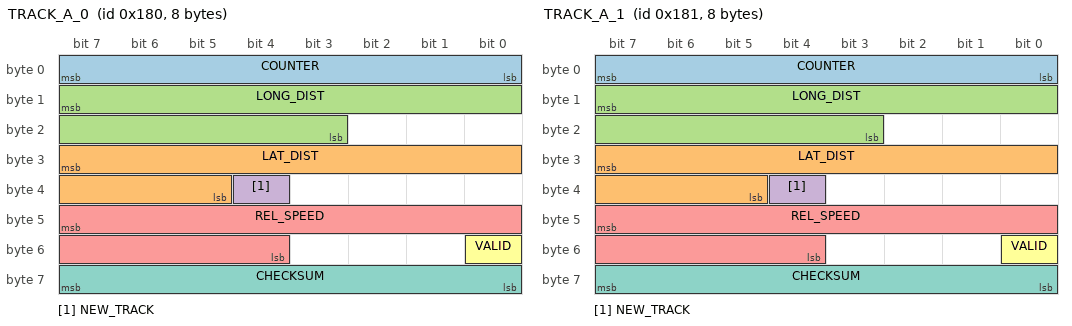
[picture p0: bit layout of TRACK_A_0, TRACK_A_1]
BO_ 384 TRACK_A_0: 8 XXX
 SG_ COUNTER : 7|8@0+ (1,0) [0|255] "" XXX
 SG_ LAT_DIST : 31|11@0- (0.04,0) [-50|50] "m" XXX
 SG_ LONG_DIST : 15|13@0+ (0.04,0) [0|300] "m" XXX
 SG_ NEW_TRACK : 36|1@0+ (1,0) [0|1] "" XXX
 SG_ REL_SPEED : 47|12@0- (0.025,0) [-100|100] "m/s" XXX
 SG_ VALID : 48|1@0+ (1,0) [0|1] "" XXX
 SG_ CHECKSUM : 63|8@0+ (1,0) [0|255] "" XXX

BO_ 385 TRACK_A_1: 8 XXX
 SG_ COUNTER : 7|8@0+ (1,0) [0|255] "" XXX
 SG_ LAT_DIST : 31|11@0- (0.04,0) [-50|50] "m" XXX
 SG_ LONG_DIST : 15|13@0+ (0.04,0) [0|300] "m" XXX
 SG_ NEW_TRACK : 36|1@0+ (1,0) [0|1] "" XXX
 SG_ REL_SPEED : 47|12@0- (0.025,0) [-100|100] "m/s" XXX
 SG_ VALID : 48|1@0+ (1,0) [0|1] "" XXX
 SG_ CHECKSUM : 63|8@0+ (1,0) [0|255] "" XXX

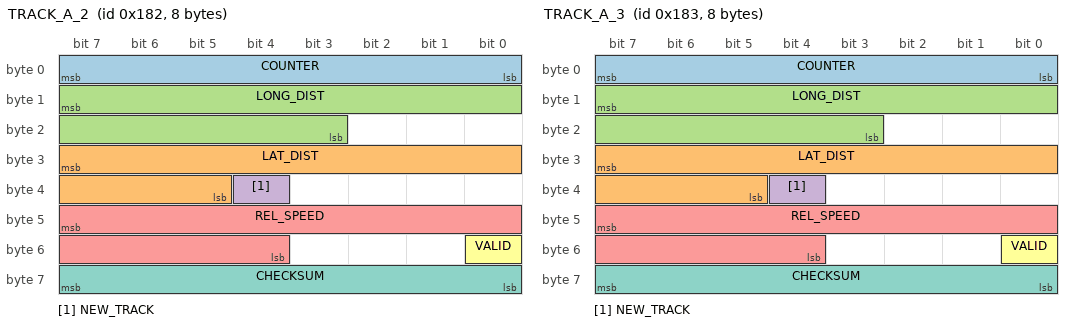
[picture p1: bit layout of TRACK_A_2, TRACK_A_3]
BO_ 386 TRACK_A_2: 8 XXX
 SG_ COUNTER : 7|8@0+ (1,0) [0|255] "" XXX
 SG_ LAT_DIST : 31|11@0- (0.04,0) [-50|50] "m" XXX
 SG_ LONG_DIST : 15|13@0+ (0.04,0) [0|300] "m" XXX
 SG_ NEW_TRACK : 36|1@0+ (1,0) [0|1] "" XXX
 SG_ REL_SPEED : 47|12@0- (0.025,0) [-100|100] "m/s" XXX
 SG_ VALID : 48|1@0+ (1,0) [0|1] "" XXX
 SG_ CHECKSUM : 63|8@0+ (1,0) [0|255] "" XXX

BO_ 387 TRACK_A_3: 8 XXX
 SG_ COUNTER : 7|8@0+ (1,0) [0|255] "" XXX
 SG_ LAT_DIST : 31|11@0- (0.04,0) [-50|50] "m" XXX
 SG_ LONG_DIST : 15|13@0+ (0.04,0) [0|300] "m" XXX
 SG_ NEW_TRACK : 36|1@0+ (1,0) [0|1] "" XXX
 SG_ REL_SPEED : 47|12@0- (0.025,0) [-100|100] "m/s" XXX
 SG_ VALID : 48|1@0+ (1,0) [0|1] "" XXX
 SG_ CHECKSUM : 63|8@0+ (1,0) [0|255] "" XXX

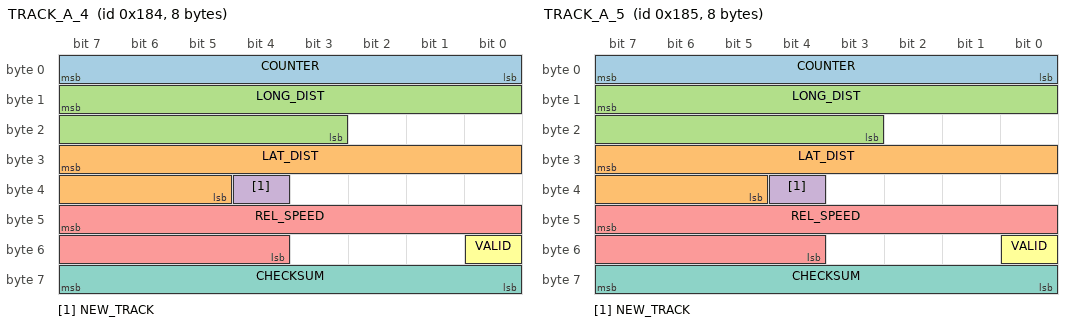
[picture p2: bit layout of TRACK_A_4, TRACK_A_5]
BO_ 388 TRACK_A_4: 8 XXX
 SG_ COUNTER : 7|8@0+ (1,0) [0|255] "" XXX
 SG_ LAT_DIST : 31|11@0- (0.04,0) [-50|50] "m" XXX
 SG_ LONG_DIST : 15|13@0+ (0.04,0) [0|300] "m" XXX
 SG_ NEW_TRACK : 36|1@0+ (1,0) [0|1] "" XXX
 SG_ REL_SPEED : 47|12@0- (0.025,0) [-100|100] "m/s" XXX
 SG_ VALID : 48|1@0+ (1,0) [0|1] "" XXX
 SG_ CHECKSUM : 63|8@0+ (1,0) [0|255] "" XXX

BO_ 389 TRACK_A_5: 8 XXX
 SG_ COUNTER : 7|8@0+ (1,0) [0|255] "" XXX
 SG_ LAT_DIST : 31|11@0- (0.04,0) [-50|50] "m" XXX
 SG_ LONG_DIST : 15|13@0+ (0.04,0) [0|300] "m" XXX
 SG_ NEW_TRACK : 36|1@0+ (1,0) [0|1] "" XXX
 SG_ REL_SPEED : 47|12@0- (0.025,0) [-100|100] "m/s" XXX
 SG_ VALID : 48|1@0+ (1,0) [0|1] "" XXX
 SG_ CHECKSUM : 63|8@0+ (1,0) [0|255] "" XXX

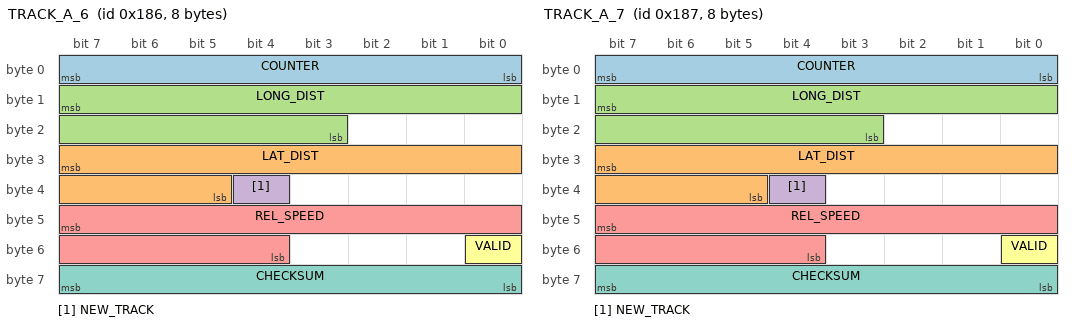
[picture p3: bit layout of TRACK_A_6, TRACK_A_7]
BO_ 390 TRACK_A_6: 8 XXX
 SG_ COUNTER : 7|8@0+ (1,0) [0|255] "" XXX
 SG_ LAT_DIST : 31|11@0- (0.04,0) [-50|50] "m" XXX
 SG_ LONG_DIST : 15|13@0+ (0.04,0) [0|300] "m" XXX
 SG_ NEW_TRACK : 36|1@0+ (1,0) [0|1] "" XXX
 SG_ REL_SPEED : 47|12@0- (0.025,0) [-100|100] "m/s" XXX
 SG_ VALID : 48|1@0+ (1,0) [0|1] "" XXX
 SG_ CHECKSUM : 63|8@0+ (1,0) [0|255] "" XXX

BO_ 391 TRACK_A_7: 8 XXX
 SG_ COUNTER : 7|8@0+ (1,0) [0|255] "" XXX
 SG_ LAT_DIST : 31|11@0- (0.04,0) [-50|50] "m" XXX
 SG_ LONG_DIST : 15|13@0+ (0.04,0) [0|300] "m" XXX
 SG_ NEW_TRACK : 36|1@0+ (1,0) [0|1] "" XXX
 SG_ REL_SPEED : 47|12@0- (0.025,0) [-100|100] "m/s" XXX
 SG_ VALID : 48|1@0+ (1,0) [0|1] "" XXX
 SG_ CHECKSUM : 63|8@0+ (1,0) [0|255] "" XXX

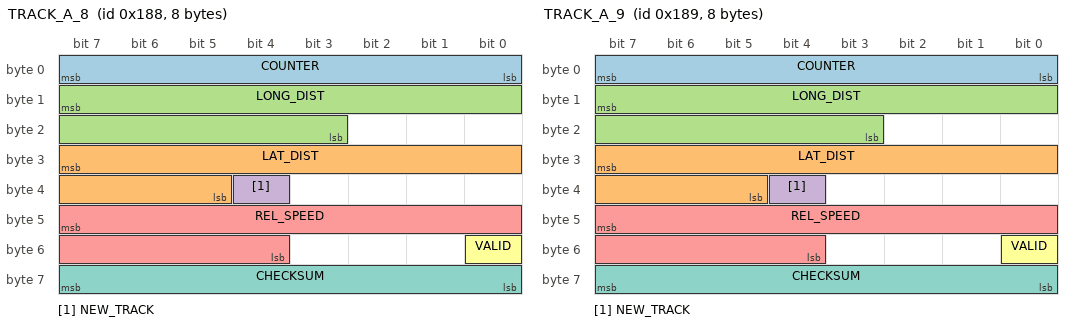
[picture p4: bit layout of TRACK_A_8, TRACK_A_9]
BO_ 392 TRACK_A_8: 8 XXX
 SG_ COUNTER : 7|8@0+ (1,0) [0|255] "" XXX
 SG_ LAT_DIST : 31|11@0- (0.04,0) [-50|50] "m" XXX
 SG_ LONG_DIST : 15|13@0+ (0.04,0) [0|300] "m" XXX
 SG_ NEW_TRACK : 36|1@0+ (1,0) [0|1] "" XXX
 SG_ REL_SPEED : 47|12@0- (0.025,0) [-100|100] "m/s" XXX
 SG_ VALID : 48|1@0+ (1,0) [0|1] "" XXX
 SG_ CHECKSUM : 63|8@0+ (1,0) [0|255] "" XXX

BO_ 393 TRACK_A_9: 8 XXX
 SG_ COUNTER : 7|8@0+ (1,0) [0|255] "" XXX
 SG_ LAT_DIST : 31|11@0- (0.04,0) [-50|50] "m" XXX
 SG_ LONG_DIST : 15|13@0+ (0.04,0) [0|300] "m" XXX
 SG_ NEW_TRACK : 36|1@0+ (1,0) [0|1] "" XXX
 SG_ REL_SPEED : 47|12@0- (0.025,0) [-100|100] "m/s" XXX
 SG_ VALID : 48|1@0+ (1,0) [0|1] "" XXX
 SG_ CHECKSUM : 63|8@0+ (1,0) [0|255] "" XXX

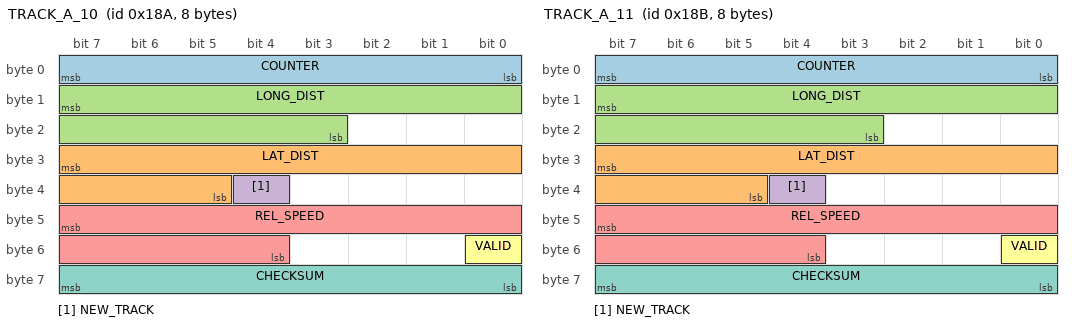
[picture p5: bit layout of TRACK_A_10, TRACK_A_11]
BO_ 394 TRACK_A_10: 8 XXX
 SG_ COUNTER : 7|8@0+ (1,0) [0|255] "" XXX
 SG_ LAT_DIST : 31|11@0- (0.04,0) [-50|50] "m" XXX
 SG_ LONG_DIST : 15|13@0+ (0.04,0) [0|300] "m" XXX
 SG_ NEW_TRACK : 36|1@0+ (1,0) [0|1] "" XXX
 SG_ REL_SPEED : 47|12@0- (0.025,0) [-100|100] "m/s" XXX
 SG_ VALID : 48|1@0+ (1,0) [0|1] "" XXX
 SG_ CHECKSUM : 63|8@0+ (1,0) [0|255] "" XXX

BO_ 395 TRACK_A_11: 8 XXX
 SG_ COUNTER : 7|8@0+ (1,0) [0|255] "" XXX
 SG_ LAT_DIST : 31|11@0- (0.04,0) [-50|50] "m" XXX
 SG_ LONG_DIST : 15|13@0+ (0.04,0) [0|300] "m" XXX
 SG_ NEW_TRACK : 36|1@0+ (1,0) [0|1] "" XXX
 SG_ REL_SPEED : 47|12@0- (0.025,0) [-100|100] "m/s" XXX
 SG_ VALID : 48|1@0+ (1,0) [0|1] "" XXX
 SG_ CHECKSUM : 63|8@0+ (1,0) [0|255] "" XXX

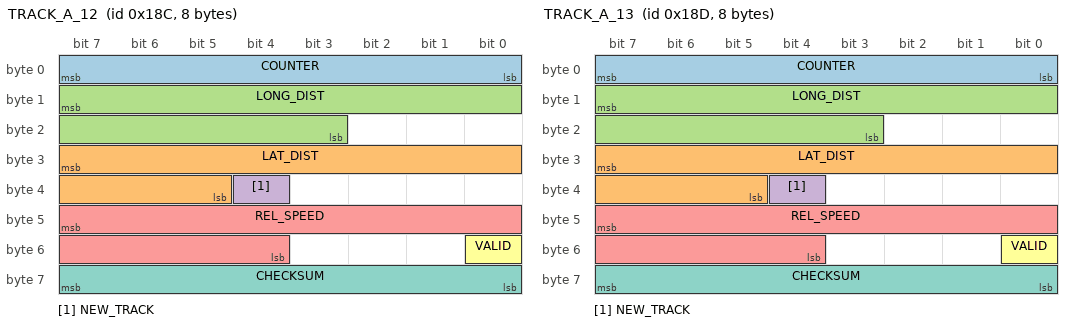
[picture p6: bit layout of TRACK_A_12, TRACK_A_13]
BO_ 396 TRACK_A_12: 8 XXX
 SG_ COUNTER : 7|8@0+ (1,0) [0|255] "" XXX
 SG_ LAT_DIST : 31|11@0- (0.04,0) [-50|50] "m" XXX
 SG_ LONG_DIST : 15|13@0+ (0.04,0) [0|300] "m" XXX
 SG_ NEW_TRACK : 36|1@0+ (1,0) [0|1] "" XXX
 SG_ REL_SPEED : 47|12@0- (0.025,0) [-100|100] "m/s" XXX
 SG_ VALID : 48|1@0+ (1,0) [0|1] "" XXX
 SG_ CHECKSUM : 63|8@0+ (1,0) [0|255] "" XXX

BO_ 397 TRACK_A_13: 8 XXX
 SG_ COUNTER : 7|8@0+ (1,0) [0|255] "" XXX
 SG_ LAT_DIST : 31|11@0- (0.04,0) [-50|50] "m" XXX
 SG_ LONG_DIST : 15|13@0+ (0.04,0) [0|300] "m" XXX
 SG_ NEW_TRACK : 36|1@0+ (1,0) [0|1] "" XXX
 SG_ REL_SPEED : 47|12@0- (0.025,0) [-100|100] "m/s" XXX
 SG_ VALID : 48|1@0+ (1,0) [0|1] "" XXX
 SG_ CHECKSUM : 63|8@0+ (1,0) [0|255] "" XXX

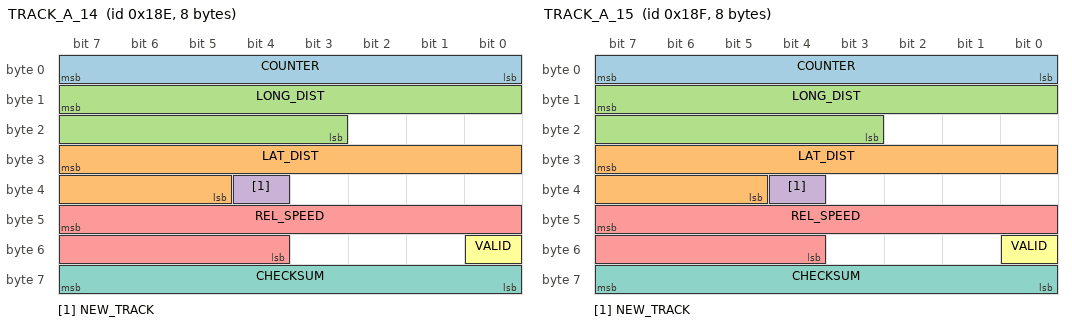
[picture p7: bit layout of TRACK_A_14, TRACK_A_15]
BO_ 398 TRACK_A_14: 8 XXX
 SG_ COUNTER : 7|8@0+ (1,0) [0|255] "" XXX
 SG_ LAT_DIST : 31|11@0- (0.04,0) [-50|50] "m" XXX
 SG_ LONG_DIST : 15|13@0+ (0.04,0) [0|300] "m" XXX
 SG_ NEW_TRACK : 36|1@0+ (1,0) [0|1] "" XXX
 SG_ REL_SPEED : 47|12@0- (0.025,0) [-100|100] "m/s" XXX
 SG_ VALID : 48|1@0+ (1,0) [0|1] "" XXX
 SG_ CHECKSUM : 63|8@0+ (1,0) [0|255] "" XXX

BO_ 399 TRACK_A_15: 8 XXX
 SG_ COUNTER : 7|8@0+ (1,0) [0|255] "" XXX
 SG_ LAT_DIST : 31|11@0- (0.04,0) [-50|50] "m" XXX
 SG_ LONG_DIST : 15|13@0+ (0.04,0) [0|300] "m" XXX
 SG_ NEW_TRACK : 36|1@0+ (1,0) [0|1] "" XXX
 SG_ REL_SPEED : 47|12@0- (0.025,0) [-100|100] "m/s" XXX
 SG_ VALID : 48|1@0+ (1,0) [0|1] "" XXX
 SG_ CHECKSUM : 63|8@0+ (1,0) [0|255] "" XXX

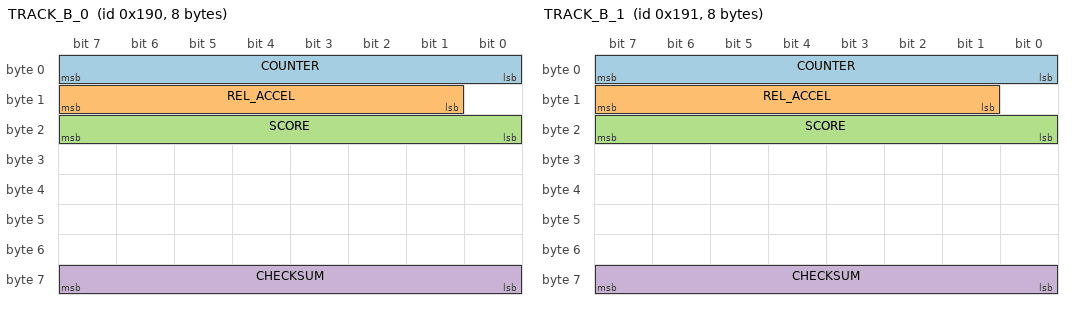
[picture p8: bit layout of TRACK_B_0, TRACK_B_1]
BO_ 400 TRACK_B_0: 8 XXX
 SG_ COUNTER : 7|8@0+ (1,0) [0|255] "" XXX
 SG_ REL_ACCEL : 15|7@0- (1,0) [-64|63] "" XXX
 SG_ SCORE : 23|8@0+ (1,0) [0|100] "" XXX
 SG_ CHECKSUM : 63|8@0+ (1,0) [0|255] "" XXX

BO_ 401 TRACK_B_1: 8 XXX
 SG_ COUNTER : 7|8@0+ (1,0) [0|255] "" XXX
 SG_ REL_ACCEL : 15|7@0- (1,0) [-64|63] "" XXX
 SG_ SCORE : 23|8@0+ (1,0) [0|100] "" XXX
 SG_ CHECKSUM : 63|8@0+ (1,0) [0|255] "" XXX

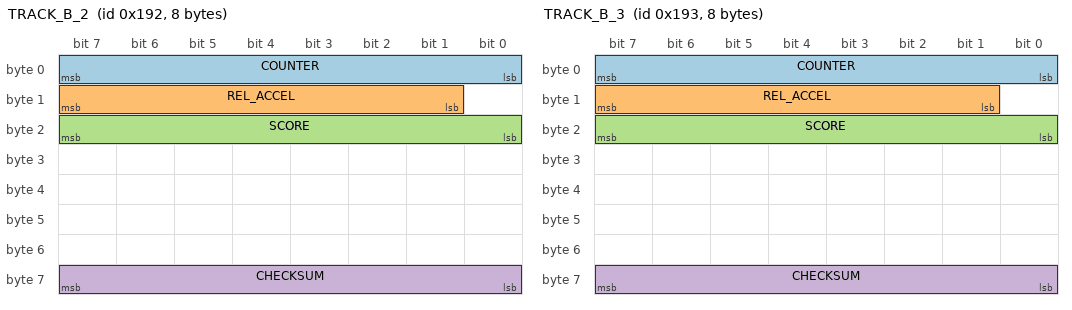
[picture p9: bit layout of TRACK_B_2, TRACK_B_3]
BO_ 402 TRACK_B_2: 8 XXX
 SG_ COUNTER : 7|8@0+ (1,0) [0|255] "" XXX
 SG_ REL_ACCEL : 15|7@0- (1,0) [-64|63] "" XXX
 SG_ SCORE : 23|8@0+ (1,0) [0|100] "" XXX
 SG_ CHECKSUM : 63|8@0+ (1,0) [0|255] "" XXX

BO_ 403 TRACK_B_3: 8 XXX
 SG_ COUNTER : 7|8@0+ (1,0) [0|255] "" XXX
 SG_ REL_ACCEL : 15|7@0- (1,0) [-64|63] "" XXX
 SG_ SCORE : 23|8@0+ (1,0) [0|100] "" XXX
 SG_ CHECKSUM : 63|8@0+ (1,0) [0|255] "" XXX

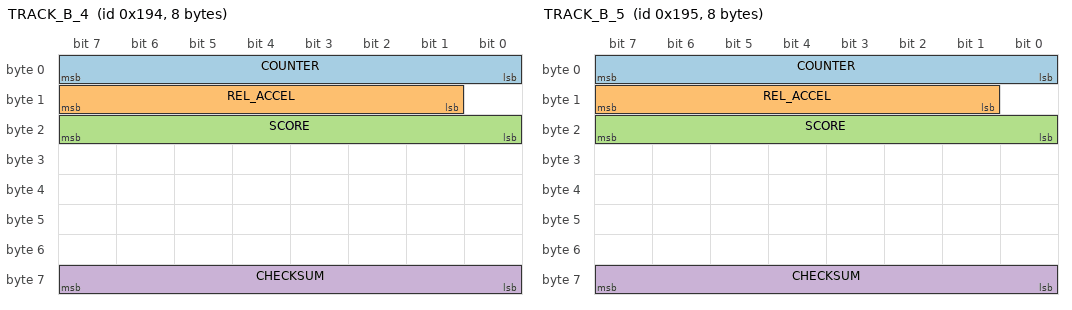
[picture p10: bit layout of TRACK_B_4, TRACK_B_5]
BO_ 404 TRACK_B_4: 8 XXX
 SG_ COUNTER : 7|8@0+ (1,0) [0|255] "" XXX
 SG_ REL_ACCEL : 15|7@0- (1,0) [-64|63] "" XXX
 SG_ SCORE : 23|8@0+ (1,0) [0|100] "" XXX
 SG_ CHECKSUM : 63|8@0+ (1,0) [0|255] "" XXX

BO_ 405 TRACK_B_5: 8 XXX
 SG_ COUNTER : 7|8@0+ (1,0) [0|255] "" XXX
 SG_ REL_ACCEL : 15|7@0- (1,0) [-64|63] "" XXX
 SG_ SCORE : 23|8@0+ (1,0) [0|100] "" XXX
 SG_ CHECKSUM : 63|8@0+ (1,0) [0|255] "" XXX

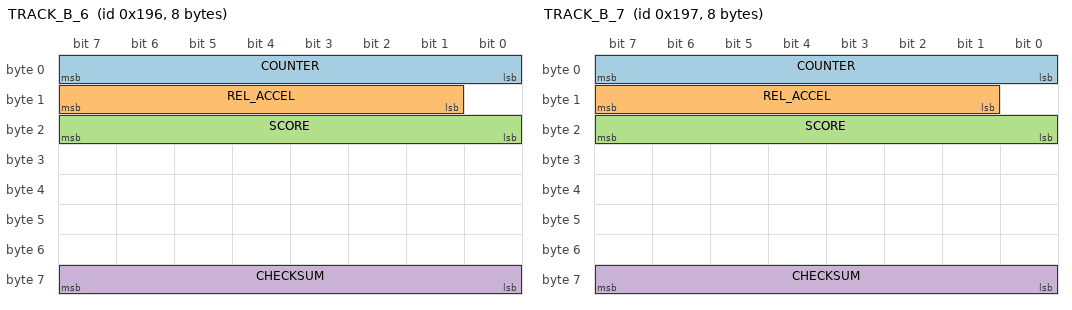
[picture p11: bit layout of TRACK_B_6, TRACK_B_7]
BO_ 406 TRACK_B_6: 8 XXX
 SG_ COUNTER : 7|8@0+ (1,0) [0|255] "" XXX
 SG_ REL_ACCEL : 15|7@0- (1,0) [-64|63] "" XXX
 SG_ SCORE : 23|8@0+ (1,0) [0|100] "" XXX
 SG_ CHECKSUM : 63|8@0+ (1,0) [0|255] "" XXX

BO_ 407 TRACK_B_7: 8 XXX
 SG_ COUNTER : 7|8@0+ (1,0) [0|255] "" XXX
 SG_ REL_ACCEL : 15|7@0- (1,0) [-64|63] "" XXX
 SG_ SCORE : 23|8@0+ (1,0) [0|100] "" XXX
 SG_ CHECKSUM : 63|8@0+ (1,0) [0|255] "" XXX

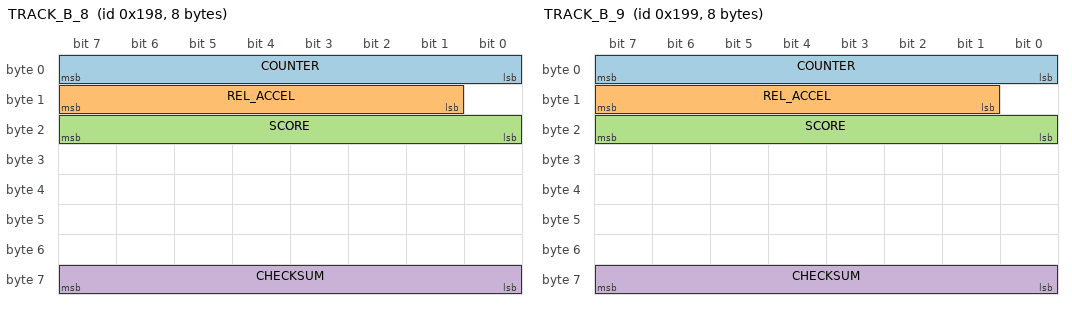
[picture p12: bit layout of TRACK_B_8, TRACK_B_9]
BO_ 408 TRACK_B_8: 8 XXX
 SG_ COUNTER : 7|8@0+ (1,0) [0|255] "" XXX
 SG_ REL_ACCEL : 15|7@0- (1,0) [-64|63] "" XXX
 SG_ SCORE : 23|8@0+ (1,0) [0|100] "" XXX
 SG_ CHECKSUM : 63|8@0+ (1,0) [0|255] "" XXX

BO_ 409 TRACK_B_9: 8 XXX
 SG_ COUNTER : 7|8@0+ (1,0) [0|255] "" XXX
 SG_ REL_ACCEL : 15|7@0- (1,0) [-64|63] "" XXX
 SG_ SCORE : 23|8@0+ (1,0) [0|100] "" XXX
 SG_ CHECKSUM : 63|8@0+ (1,0) [0|255] "" XXX

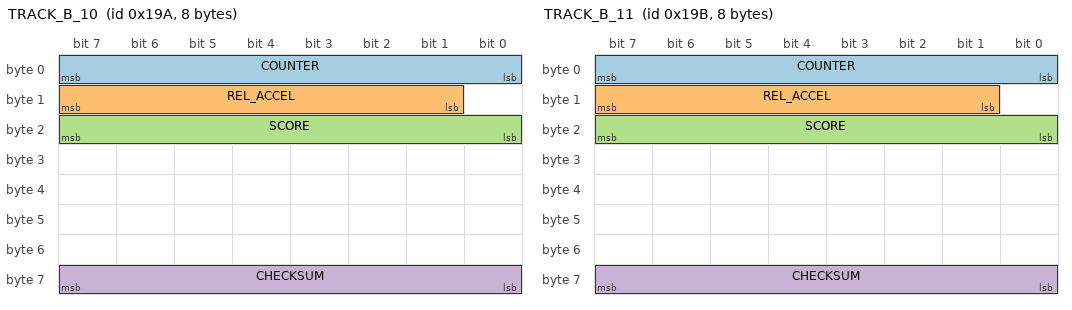
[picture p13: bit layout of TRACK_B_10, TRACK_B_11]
BO_ 410 TRACK_B_10: 8 XXX
 SG_ COUNTER : 7|8@0+ (1,0) [0|255] "" XXX
 SG_ REL_ACCEL : 15|7@0- (1,0) [-64|63] "" XXX
 SG_ SCORE : 23|8@0+ (1,0) [0|100] "" XXX
 SG_ CHECKSUM : 63|8@0+ (1,0) [0|255] "" XXX

BO_ 411 TRACK_B_11: 8 XXX
 SG_ COUNTER : 7|8@0+ (1,0) [0|255] "" XXX
 SG_ REL_ACCEL : 15|7@0- (1,0) [-64|63] "" XXX
 SG_ SCORE : 23|8@0+ (1,0) [0|100] "" XXX
 SG_ CHECKSUM : 63|8@0+ (1,0) [0|255] "" XXX

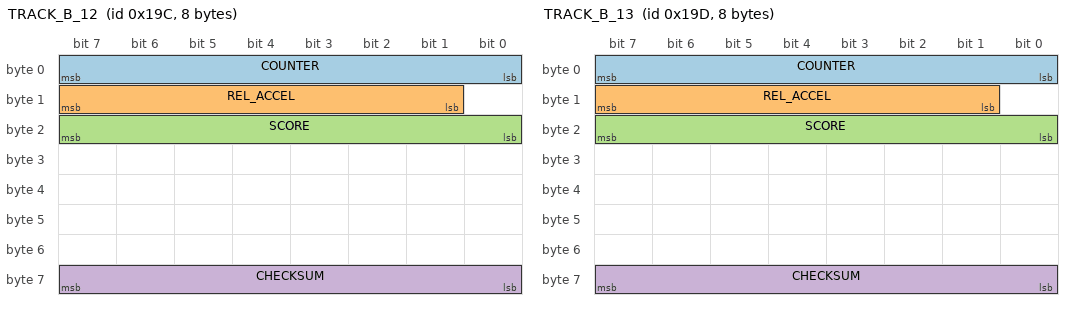
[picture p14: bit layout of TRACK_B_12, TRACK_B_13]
BO_ 412 TRACK_B_12: 8 XXX
 SG_ COUNTER : 7|8@0+ (1,0) [0|255] "" XXX
 SG_ REL_ACCEL : 15|7@0- (1,0) [-64|63] "" XXX
 SG_ SCORE : 23|8@0+ (1,0) [0|100] "" XXX
 SG_ CHECKSUM : 63|8@0+ (1,0) [0|255] "" XXX

BO_ 413 TRACK_B_13: 8 XXX
 SG_ COUNTER : 7|8@0+ (1,0) [0|255] "" XXX
 SG_ REL_ACCEL : 15|7@0- (1,0) [-64|63] "" XXX
 SG_ SCORE : 23|8@0+ (1,0) [0|100] "" XXX
 SG_ CHECKSUM : 63|8@0+ (1,0) [0|255] "" XXX

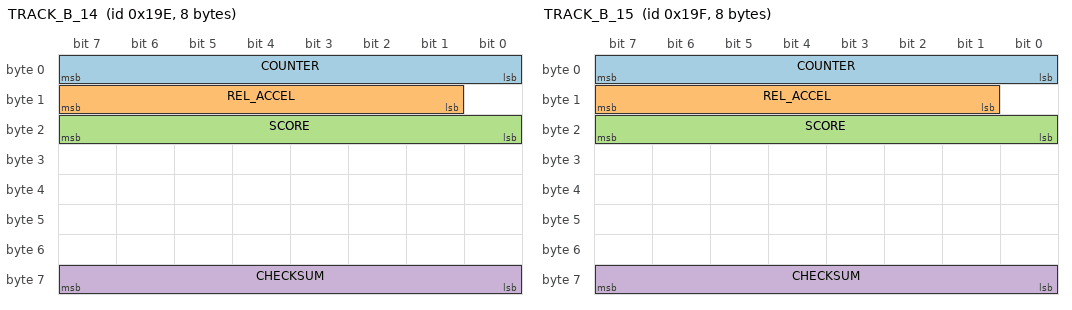
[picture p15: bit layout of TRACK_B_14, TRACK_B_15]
BO_ 414 TRACK_B_14: 8 XXX
 SG_ COUNTER : 7|8@0+ (1,0) [0|255] "" XXX
 SG_ REL_ACCEL : 15|7@0- (1,0) [-64|63] "" XXX
 SG_ SCORE : 23|8@0+ (1,0) [0|100] "" XXX
 SG_ CHECKSUM : 63|8@0+ (1,0) [0|255] "" XXX

BO_ 415 TRACK_B_15: 8 XXX
 SG_ COUNTER : 7|8@0+ (1,0) [0|255] "" XXX
 SG_ REL_ACCEL : 15|7@0- (1,0) [-64|63] "" XXX
 SG_ SCORE : 23|8@0+ (1,0) [0|100] "" XXX
 SG_ CHECKSUM : 63|8@0+ (1,0) [0|255] "" XXX

BO_ 576 NEW_MSG_1: 8 XXX
 SG_ NEW_SIGNAL_1 : 15|7@0+ (1,0) [0|127] "" XXX
 SG_ NEW_SIGNAL_2 : 23|8@0+ (1,0) [0|255] "" XXX

BU_: XXX

CM_ "AUTOGENERATED FILE, DO NOT EDIT";

CM_ "Imported file _comma.dbc starts here";
CM_ "BO_ STEERING_IPAS_COMMA: Copy of msg 614 so we can do angle control while the Park Assist ECU is connected (Panda spoofs 614 with 359 on connector J70). Note that addresses 0x266 and 0x167 are checksum-invariant";

CM_ "BO_ SECONDARY_STEER_ANGLE: ZSS is a high-precision steering angle sensor that can replace the lower resolution sensor in most TSS1 Toyotas. Learn more: https://github.com/commaai/openpilot/wiki/Toyota-Lexus#zorro-steering-sensor-zss";

CM_ "BO_ SDSU: The sDSU is a modified DSU for use in TSS1 Toyotas. Learn more: https://github.com/wocsor/panda/tree/smart_dsu";
CM_ SG_ 767 FD_BUTTON "The follow distance button signal as forwarded by the sdsu";

CM_ "Imported file _toyota_2017.dbc starts here";
CM_ SG_ 36 YAW_RATE "verify";
CM_ SG_ 36 ACCEL_X "x-axis accel";
CM_ SG_ 37 STEER_FRACTION "1/15th of the signal STEER_ANGLE, which is 1.5 deg; note that 0x8 is never set";
CM_ SG_ 37 STEER_RATE "factor is tbd";
CM_ SG_ 466 NEUTRAL_FORCE "force in newtons the engine/electric motors are applying without any acceleration commands or user input";
CM_ SG_ 466 ACC_BRAKING "whether brakes are being actuated from ACC command";
CM_ SG_ 466 ACCEL_NET "net acceleration produced by the system, given ACCEL_CMD, road grade and other factors";
CM_ SG_ 466 CRUISE_STATE "Active state is 8, if standstill is requested will switch to state 11(3 sec timer), after timer is elapsed will switch into state 7(standstill). If plus button was pressed - status 9, minus button pressed - status 10";
CM_ SG_ 467 ACC_FAULTED "1 when ACC is faulted and the PCM disallows engagement";
CM_ SG_ 467 SET_SPEED "43 km/h are shown as 28 mph, so conversion isn't perfect";
CM_ SG_ 467 LOW_SPEED_LOCKOUT "in low speed lockout, system would always disengage below 28mph";
CM_ SG_ 560 BRAKE_PRESSED "another brake pressed?";
CM_ SG_ 581 GAS_PEDAL "it seems slightly filtered";
CM_ SG_ 608 STEER_TORQUE_DRIVER "driver torque";
CM_ SG_ 608 STEER_OVERRIDE "set when driver torque exceeds a certain value";
CM_ SG_ 614 ANGLE "set to measured angle when ipas control isn't active";
CM_ SG_ 643 _COUNTER "only used on cars that use this msg for cruise control";
CM_ SG_ 643 BRAKE_STATUS "only used on cars that use this msg for cruise control";
CM_ SG_ 643 PRECOLLISION_ACTIVE "set 0.5s before any braking";
CM_ SG_ 835 ACC_TYPE "if 2, car is likely to have a permanent low speed lockout. 1 is ok";
CM_ SG_ 835 RADAR_DIRTY "Display Clean Radar Sensor message on HUD";
CM_ SG_ 835 ACC_MALFUNCTION "display ACC fault on dash if set to 1";
CM_ SG_ 835 ACC_CUT_IN "Display blinking yellow lead if set to 1";
CM_ SG_ 835 DISTANCE "Cycle through ACC following distance from long, mid, short when set to 1";
CM_ SG_ 835 ITS_CONNECT_LEAD "Displayed when lead car is capable of ITS Connect";
CM_ SG_ 835 ALLOW_LONG_PRESS "Enable Toyota's factory set speed increment behaviour, available on both metrics cars and imperial unit cars";
CM_ SG_ 835 PERMIT_BRAKING "Original ACC has this going high when a car in front is detected. In openpilot and before the PERMIT_BRAKING name, this was 'SET_ME_1' and is hardcoded to be high. Unsure if only informational or has an effect though existing usage in openpilot is to always set it to 1. Originally 'PMTBRKG' in the leaked toyota_2017_ref_pt.dbc file and name expansion speculated to be PerMiT BRaKinG.";
CM_ SG_ 835 ACCEL_CMD_ALT "Copy of main ACCEL_CMD, but across 8 bits instead of 16 bits like ACCEL_CMD. Unsure if only informational or has an effect. Likely informational as existing openpilot sets this to 0 and no loss of functionality observed. Originally 'AT_RAW' in leaked toyota_2017_ref_pt.dbc file.";
CM_ SG_ 865 GAS_PEDAL_ALT "copy of main GAS_PEDAL. Both use 8 bits. Might indicate that this message is for pedals.";
CM_ SG_ 865 CLUTCH_RELEASED "boolean of clutch for 6MT.";
CM_ SG_ 865 ACC_FAULTED "1 when ACC is faulted and the PCM disallows engagement. Also describes a lockout when the ACC_CONTROL->ACC_MALFUNCTION bit is set.";
CM_ SG_ 921 UI_SET_SPEED "set speed shown in the vehicle's UI with the vehicle's unit";
CM_ SG_ 921 TEMP_ACC_FAULTED "1 when the UI is displaying or playing fault-related alerts or sounds. Also 1 when pressing main on.";
CM_ SG_ 951 BRAKE_LIGHTS_ACC "brake lights when ACC commands decel";
CM_ SG_ 956 GEAR "on 6MT, only R shows.";
CM_ SG_ 1009 UI_SET_SPEED "units seem to be whatever the car is set to";
CM_ SG_ 1041 PCS_INDICATOR "Pre-Collision System Indicator";
CM_ SG_ 1041 PCS_SENSITIVITY "Pre-Collision System Sensitivity";
CM_ SG_ 1041 PCS_DUST "alert: Front Camera Low Visibility Unavailable See Owner's Manual";
CM_ SG_ 1041 PCS_DUST2 "alert: Pre-Collision System Radar Sensor Blocked Unavailable Clean Radar Sensor";
CM_ SG_ 1041 PCS_TEMP "alert: Front Camera Out of Temperature Range Unavailable Wait until Normal Temperature";
CM_ SG_ 1041 PCS_TEMP2 "alert: Pre-Collision System Out of Temperature Range Unavailable See Owner's Manual";
CM_ SG_ 1041 FRD_ADJ "alert: ERROR ADJUSTING FRONT RADAR BEAM";
CM_ SG_ 1042 LDA_SA_TOGGLE "LDA Steering Assist Toggle";
CM_ SG_ 1042 LDW_EXIST "Unclear what this is, it's usually set to 0";
CM_ SG_ 1042 LDA_SENSITIVITY "LDA Sensitivity";
CM_ SG_ 1042 LDA_ON_MESSAGE "Display LDA Turned ON message";
CM_ SG_ 1042 REPEATED_BEEPS "LDA audible warning";
CM_ SG_ 1042 LDA_UNAVAILABLE_QUIET "LDA toggles and sensitivity settings are greyed out if set to 1";
CM_ SG_ 1042 LDA_MESSAGES "Various LDA Messages";
CM_ SG_ 1042 LDA_FRONT_CAMERA_BLOCKED "originally LDAFCVB, LDA related settings are greyed out if set to 1";
CM_ SG_ 1042 TAKE_CONTROL "Please Control Steering Wheel warning";
CM_ SG_ 1042 LANE_SWAY_TOGGLE "Lane Sway Warning System SWS Switch";
CM_ SG_ 1042 LANE_SWAY_WARNING "Lane Sway Warning System Triggered";
CM_ SG_ 1042 LANE_SWAY_FLD "Unknown signal for Lane Sway Warning System, set to 7 on stock system when SWS is enabled, 0 when SWS is disabled";
CM_ SG_ 1042 LANE_SWAY_BUZZER "Similar to TWO_BEEPS";
CM_ SG_ 1042 SET_ME_X01 "empty bit on leaked dbc, always set to 1 during normal operations";
CM_ SG_ 1042 SET_ME_X02 "empty bit on leaked dbc, always set to 2 during normal operations";
CM_ SG_ 1083 STATE "when the dashboard button is pressed, the value changes from zero to non-zero";
CM_ SG_ 1161 SPDVAL1 "Numbers 0-199 is displayed, 200-254 displays circle without number and 255 is for no limit.";
CM_ SG_ 1161 SYNCID1 "counter from 1 to f at 1 Hz";
CM_ SG_ 1161 SPDVAL2 "conditional speed value 70";
CM_ SG_ 1162 SGNNUMP "1 if SPDVAL1 is set, otherwise 0";
CM_ SG_ 1162 SYNCID2 "counter from 1 to f at 1 Hz";
CM_ SG_ 1163 TSREQPD "always 1";
CM_ SG_ 1163 TSRMSW "always 1";
CM_ SG_ 1163 OTSGNNTM "always 3";
CM_ SG_ 1163 NTLVLSPD "always 3";
CM_ SG_ 1163 OVSPNTM "always 3";
CM_ SG_ 1163 OVSPVALL "-5 at start then 2 after 2 seconds";
CM_ SG_ 1163 OVSPVALM "-5 at start then 5 after 2 seconds";
CM_ SG_ 1163 OVSPVALH "-5 at start then 10 after 2 seconds";
CM_ SG_ 1163 TSRSPU "always 1";
CM_ SG_ 1552 UI_SPEED "Does not appear to match dash";
CM_ SG_ 1552 METER_SLIDER_BRIGHTNESS_PCT "Combination display brightness setting, scales from 12 per cent to 100 per cent, reflects combination meter settings only, not linked with headlight state";
CM_ SG_ 1552 METER_SLIDER_LOW_BRIGHTNESS "Combination display low brightness mode, also controls footwell lighting";
CM_ SG_ 1552 METER_SLIDER_DIMMED "Combination display slider not at max, reflects combination meter settings only, not linked with headlight state";
CM_ SG_ 1553 ODOMETER "Unit is dependent upon units signal";
CM_ SG_ 1592 LOCK_STATUS_CHANGED "1 on rising edge of lock/unlocking";
CM_ SG_ 1592 LOCK_STATUS "The next 3 bits always seem to follow this signal.";
CM_ SG_ 1592 LOCKED_VIA_KEYFOB "1 for as long as car is locked with key fob or door handle touch";

CM_ "toyota_nodsu_pt.dbc starts here";

CM_ SG_ 401 PERCENTAGE "driver override percentage (0-100), very close to steeringPressed in OP";
CM_ SG_ 401 TORQUE_WIND_DOWN "used to wind down torque on user override";
CM_ SG_ 401 ANGLE "angle of car relative to lane center on LTA camera";
CM_ SG_ 401 STEER_ANGLE_CMD "desired angle, OEM steers up to 95 degrees, no angle limit but torque will bottom out";
CM_ SG_ 401 CLEAR_HOLD_STEERING_ALERT "set to 1 when user clears LKAS_HUD->LDA_ALERT ('Hold Steering') by applying torque to steering wheel";
CM_ SG_ 401 STEER_REQUEST "enable bit for steering, 1 to steer, 0 to not";
CM_ SG_ 401 STEER_REQUEST_2 "enable bit for steering, 1 to steer, 0 to not";
CM_ SG_ 401 LKA_ACTIVE "1 when using LTA for LKA";
CM_ SG_ 401 SETME_X1 "usually 1, seen at 0 on some South American Corollas indicating lack of stock Lane Tracing Assist";
CM_ SG_ 401 SETME_X3 "almost completely correlates with Toyota Safety Sense version, but may instead describe max torque when using LTA. if TSS 2.5 or 2022 RAV4, this is always 1. if TSS 2.0 this is always 3 (or 0 on Alphard, Highlander, NX)";
CM_ SG_ 550 BRAKE_PRESSURE "seems prop to pedal force";
CM_ SG_ 550 BRAKE_POSITION "seems proportional to pedal displacement, unclear the max value of 0x1c8";
CM_ SG_ 610 TYPE "seems 1 on Corolla, 0 on all others";
CM_ SG_ 881 GAS_PEDAL "not set on all cars, only seen on TSS 2.5 Camry Hybrid so far";
CM_ SG_ 881 STEER_ANGLE "matches STEER_TORQUE_SENSOR->STEER_ANGLE";
CM_ SG_ 881 TURN_SIGNALS "flipped on some cars";
CM_ SG_ 881 LDA_SA_TOGGLE "not applicable for all cars";
CM_ SG_ 881 LTA_STEER_REQUEST "only applicable for TSS 2.5: matches STEERING_LTA->STEER_REQUEST";
CM_ SG_ 881 UNKNOWN "related to steering wheel angle";
CM_ SG_ 881 STEERING_PRESSED "only applicable for TSS 2.5: low sensitivity steering wheel pressed by driver signal";
CM_ SG_ 1014 L_ADJACENT "vehicle adjacent left side of car. enabled above 10mph, regardless of ADJACENT_ENABLED or APPROACHING_ENABLED";
CM_ SG_ 1014 L_APPROACHING "vehicle approaching from left side of car. enabled above 10mph, regardless of ADJACENT_ENABLED or APPROACHING_ENABLED";
CM_ SG_ 1014 R_ADJACENT "vehicle adjacent right side of car. enabled above 10mph, regardless of ADJACENT_ENABLED or APPROACHING_ENABLED";
CM_ SG_ 1014 R_APPROACHING "vehicle approaching from right side of car. enabled above 10mph, regardless of ADJACENT_ENABLED or APPROACHING_ENABLED";
CM_ SG_ 1014 ADJACENT_ENABLED "when BSM is enabled in settings, this is on along with APPROACHING_ENABLED. this controls bsm alert visibility";
CM_ SG_ 1014 APPROACHING_ENABLED "when BSM is enabled in settings, this is on along with ADJACENT_ENABLED. this controls bsm alert visibility";

VAL_ 513 STATE 5 "FAULT_TIMEOUT" 4 "FAULT_STARTUP" 3 "FAULT_SCE" 2 "FAULT_SEND" 1 "FAULT_BAD_CHECKSUM" 0 "NO_FAULT" ;

VAL_ 780 CRUISE_SPEED 255 "no_speed" 252 "stopped";
VAL_ 780 HUD_LEAD 3 "acc_off" 2 "solid_car" 1 "dashed_car" 0 "no_car";
VAL_ 884 DASHBOARD_ALERT 0 "none" 51 "acc_problem" 55 "cmbs_problem" 75 "key_not_detected" 79 "fasten_seatbelt" 111 "lkas_problem" 131 "brake_system_problem" 132 "brake_hold_problem" 139 "tbd" 161 "door_open";
VAL_ 891 WIPERS 4 "High" 2 "Low" 0 "Off";

VAL_ 506 FCW 3 "fcw" 2 "fcw" 1 "fcw" 0 "no_fcw";
VAL_ 506 CHIME 4 "double_chime" 3 "single_chime" 2 "continuous_chime" 1 "repeating_chime" 0 "no_chime";
VAL_ 506 AEB_STATUS 3 "aeb_prepare" 2 "aeb_ready" 1 "aeb_braking" 0 "no_aeb";
VAL_ 829 BEEP 3 "single_beep" 2 "triple_beep" 1 "repeated_beep" 0 "no_beep";

VAL_ 399 STEER_STATUS 6 "tmp_fault" 5 "fault_1" 4 "no_torque_alert_2" 3 "low_speed_lockout" 2 "no_torque_alert_1" 0 "normal" ;
VAL_ 401 GEAR_SHIFTER 32 "L" 16 "S" 8 "D" 4 "N" 2 "R" 1 "P" ;
VAL_ 401 GEAR 7 "L" 10 "S" 4 "D" 3 "N" 2 "R" 1 "P" ;
VAL_ 422 CRUISE_BUTTONS 7 "tbd" 6 "tbd" 5 "tbd" 4 "accel_res" 3 "decel_set" 2 "cancel" 1 "main" 0 "none" ;
VAL_ 422 LIGHTS_SETTING 3 "high_beam" 2 "low_beam" 1 "position" 0 "no_lights" ;
